# CW32L010 register map
Vendor: Wuhan Xinyuan Semiconductor Co.Ltd; Series: ARMCM0P; File version: 1.2
CPU: CM0+ r0p1, little endian, no MPU, no FPU, 3 interrupt priority bits
Registers are 32-bit, read-write, no defined reset value unless marked. A register's access mark holds for its fields unless they carry their own. Offsets are from the block's base; [hi:lo] are bit positions; {n}, {i} and the like mark numbered series; 'fields as' and 'values as' point back to an identical list.

## BTIM1 — Base Timer 1
Base 0x40004800
Same registers: BTIM2 0x40004840, BTIM3 0x40004880
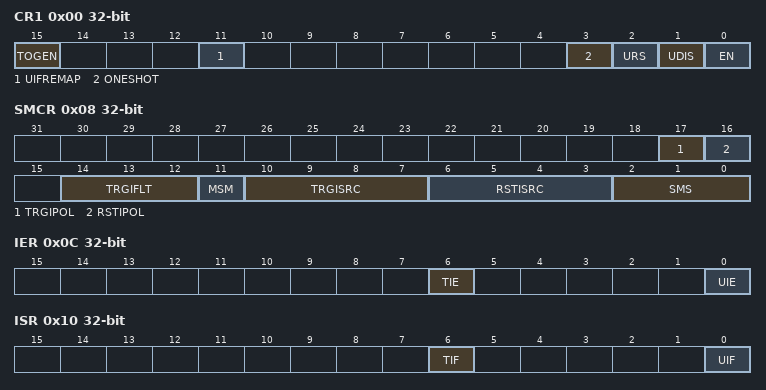
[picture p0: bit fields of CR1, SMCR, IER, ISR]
0x00 CR1 — Control register1
  [15] TOGEN
  [11] UIFREMAP — desc REMAP
  [3] ONESHOT
  [2] URS
  [1] UDIS
  [0] EN
0x04 CR2 — Control register2
  [6:4] MMS
0x08 SMCR — Slave Mode Control register
  [17] TRGIPOL, [16] RSTIPOL, [14:12] TRGIFLT, [11] MSM, [10:7] TRGISRC, [6:3] RSTISRC, [2:0] SMS
0x0C IER — Interrupt enable register
  [6] TIE, [0] UIE
0x10 ISR ro — Interrupt status register
  [6] TIF, [0] UIF
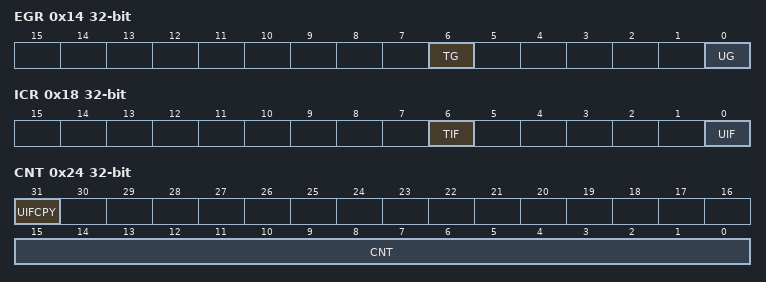
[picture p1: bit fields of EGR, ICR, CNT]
0x14 EGR wo — Event Generate register
  [6] TG, [0] UG
0x18 ICR — Interrupt flag clear register
  [6] TIF, [0] UIF
0x24 CNT — Counter Register
  [31] UIFCPY ro, [15:0] CNT
0x28 PSC — Prescaler Control Register
  [15:0] PSC
0x2C ARR — Auto Reload Register
  [15:0] ARR

## CRC
Base 0x40023000
0x00 CR — Control register
  [3:0] MODE
0x08 DR — Data register
  [7:0] DR
0x0C RESULT ro
  [15:0] RESULT

## FLASH
Base 0x40022000
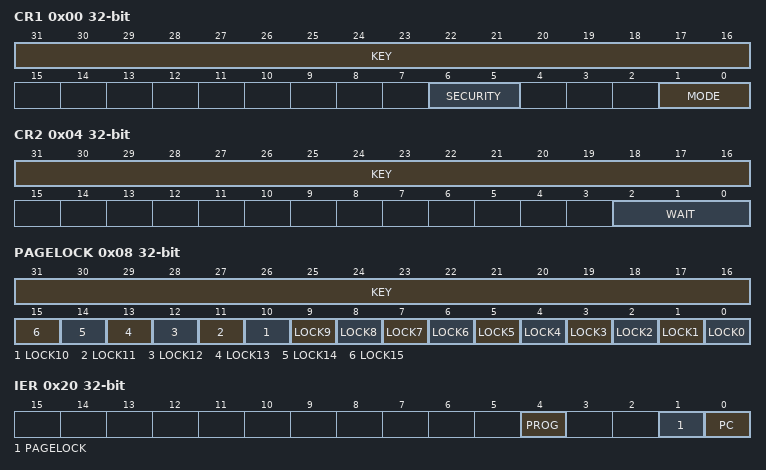
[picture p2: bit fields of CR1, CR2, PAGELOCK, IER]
0x00 CR1 — Control register1
  [31:16] KEY wo, [6:5] SECURITY ro, [1:0] MODE
0x04 CR2 — Control register2
  [31:16] KEY wo, [2:0] WAIT
0x08 PAGELOCK — Page Write Erase Lock
  [31:16] KEY wo
  [n] LOCK{n} (n=0..15) — Page{8n} - {8n+7}
0x20 IER — Interrupt enable register
  [4] PROG, [1] PAGELOCK, [0] PC
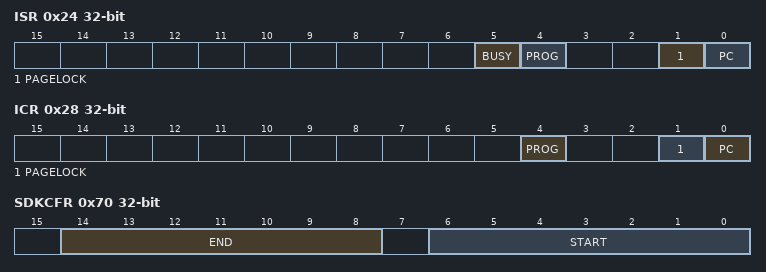
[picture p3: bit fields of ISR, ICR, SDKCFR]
0x24 ISR ro — Interrupt status register
  [5] BUSY, [4] PROG, [1] PAGELOCK, [0] PC
0x28 ICR — Interrupt flag clear register
  [4] PROG, [1] PAGELOCK, [0] PC
0x70 SDKCFR ro — SDK config register
  [14:8] END, [6:0] START

## GPIOA
Base 0x48000000
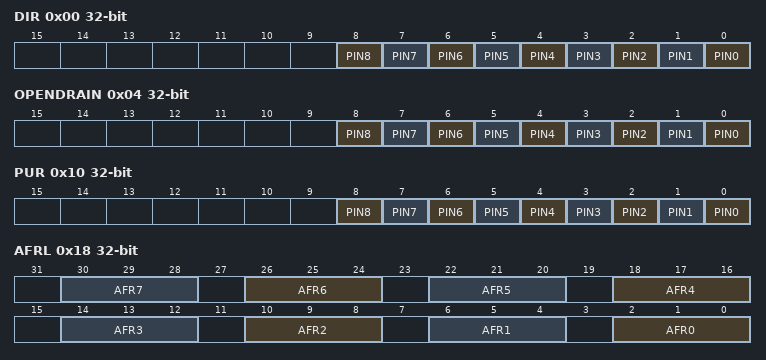
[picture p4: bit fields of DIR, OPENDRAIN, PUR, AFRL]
0x00 DIR
  [n] PIN{n} (n=0..8)
0x04 OPENDRAIN
  [n] PIN{n} (n=0..8)
0x10 PUR
  [n] PIN{n} (n=0..8)
0x14 AFRH
  [2:0] AFR8
0x18 AFRL
  [4n+2:4n] AFR{n} (n=0..7)
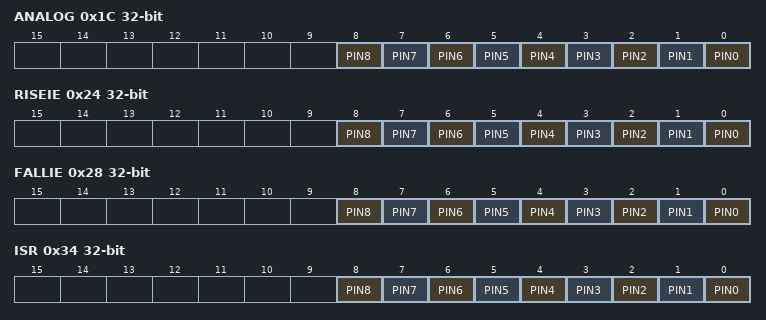
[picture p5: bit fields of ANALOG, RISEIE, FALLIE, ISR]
0x1C ANALOG
  [n] PIN{n} (n=0..8)
0x24 RISEIE — Interrupt enable register
  [n] PIN{n} (n=0..8)
0x28 FALLIE — Interrupt enable register
  [n] PIN{n} (n=0..8)
0x34 ISR — Interrupt status register
  [n] PIN{n} (n=0..8)
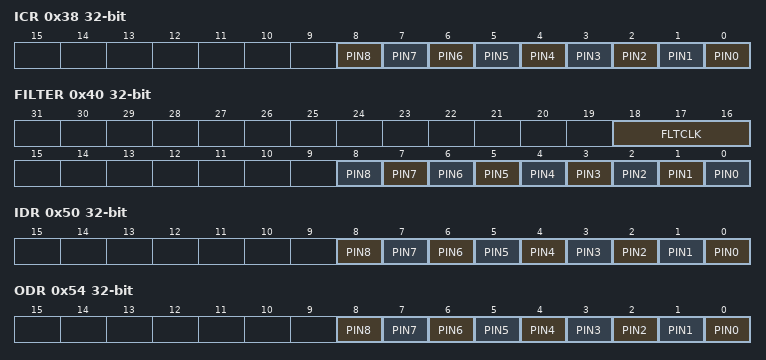
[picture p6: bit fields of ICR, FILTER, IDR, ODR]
0x38 ICR — Interrupt flag clear register
  [n] PIN{n} (n=0..8)
0x40 FILTER
  [18:16] FLTCLK, [n] PIN{n} (n=0..8)
0x50 IDR
  [n] PIN{n} (n=0..8)
0x54 ODR
  [n] PIN{n} (n=0..8)
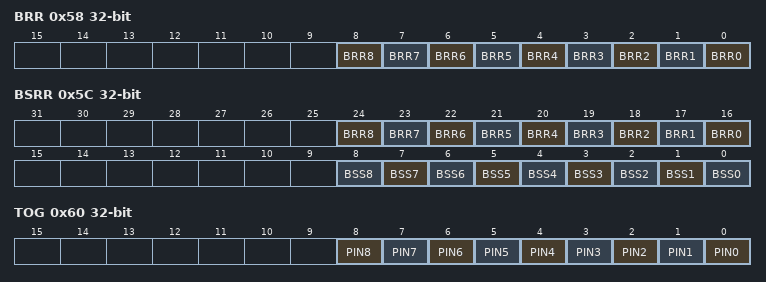
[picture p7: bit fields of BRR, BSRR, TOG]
0x58 BRR
  [n] BRR{n} (n=0..8)
0x5C BSRR
  [n+16] BRR{n} (n=0..8), [n] BSS{n} (n=0..8)
0x60 TOG
  [n] PIN{n} (n=0..8)

## GPIOB
Base 0x48000100
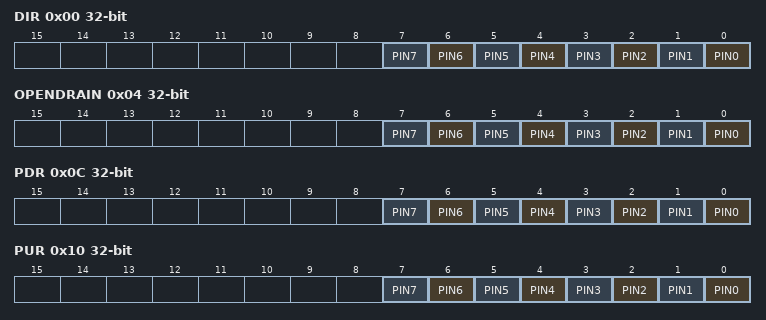
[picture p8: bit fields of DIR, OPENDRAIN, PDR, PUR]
0x00 DIR
  [n] PIN{n} (n=0..7)
0x04 OPENDRAIN
  [n] PIN{n} (n=0..7)
0x0C PDR
  [n] PIN{n} (n=0..7)
0x10 PUR
  [n] PIN{n} (n=0..7)
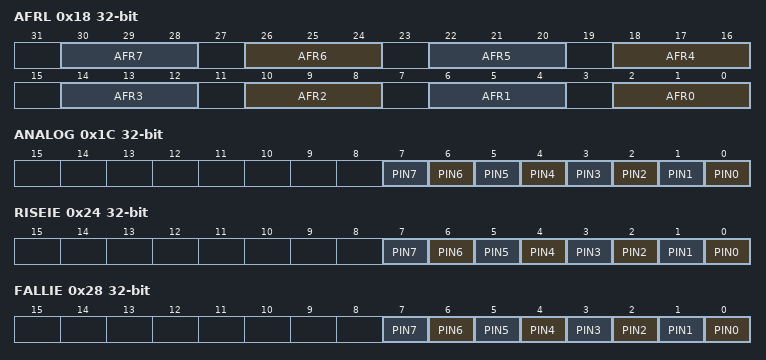
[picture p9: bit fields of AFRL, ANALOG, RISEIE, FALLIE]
0x18 AFRL
  [4n+2:4n] AFR{n} (n=0..7)
0x1C ANALOG
  [n] PIN{n} (n=0..7)
0x24 RISEIE — Interrupt enable register
  [n] PIN{n} (n=0..7)
0x28 FALLIE — Interrupt enable register
  [n] PIN{n} (n=0..7)
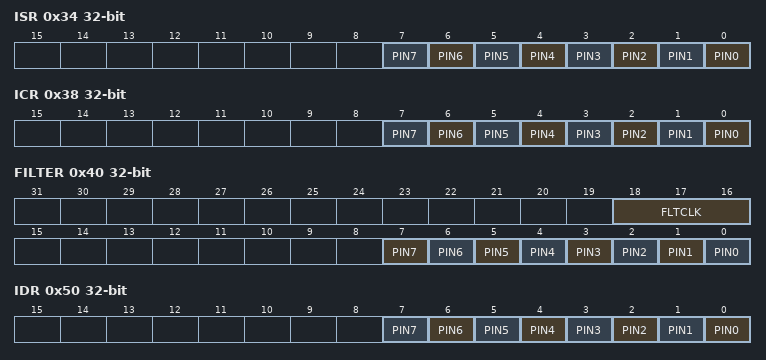
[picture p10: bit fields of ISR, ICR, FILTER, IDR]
0x34 ISR — Interrupt status register
  [n] PIN{n} (n=0..7)
0x38 ICR — Interrupt flag clear register
  [n] PIN{n} (n=0..7)
0x40 FILTER
  [18:16] FLTCLK, [n] PIN{n} (n=0..7)
0x50 IDR
  [n] PIN{n} (n=0..7)
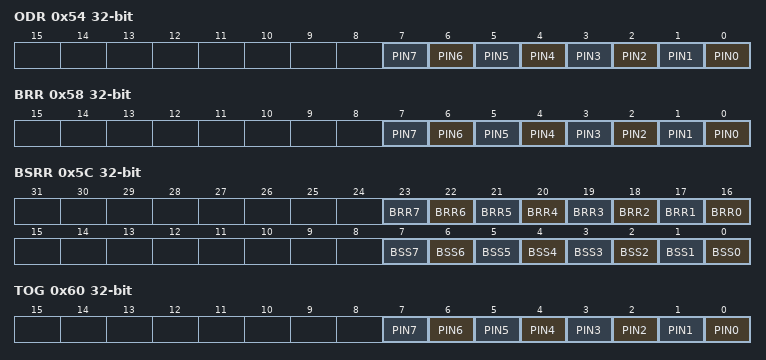
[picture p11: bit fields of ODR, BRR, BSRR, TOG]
0x54 ODR
  [n] PIN{n} (n=0..7)
0x58 BRR
  [n] PIN{n} (n=0..7)
0x5C BSRR
  [n+16] BRR{n} (n=0..7), [n] BSS{n} (n=0..7)
0x60 TOG
  [n] PIN{n} (n=0..7)

## GTIM1 — General Timer 1
Base 0x40001800
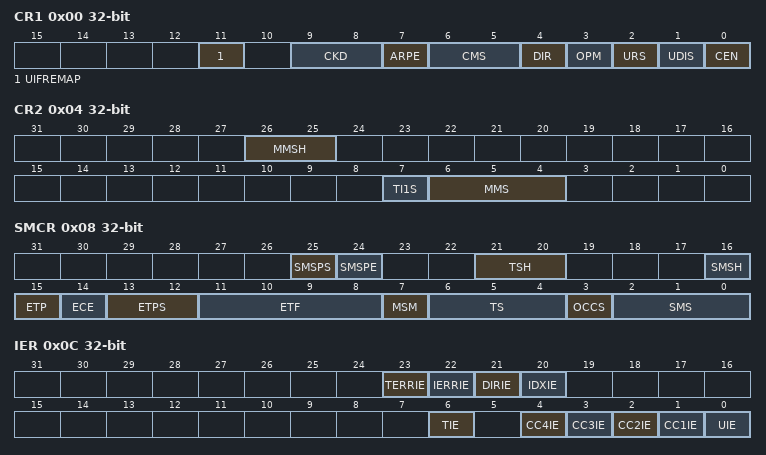
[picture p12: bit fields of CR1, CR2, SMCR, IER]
0x00 CR1 — Control register1
  [11] UIFREMAP, [9:8] CKD, [7] ARPE, [6:5] CMS, [4] DIR, [3] OPM, [2] URS, [1] UDIS, [0] CEN
0x04 CR2 — Control register2
  [26:25] MMSH, [7] TI1S, [6:4] MMS
0x08 SMCR — Slave Mode control register
  [25] SMSPS, [24] SMSPE, [21:20] TSH, [16] SMSH, [15] ETP, [14] ECE, [13:12] ETPS, [11:8] ETF, [7] MSM, [6:4] TS, [3] OCCS, [2:0] SMS
0x0C IER — Interrupt control register
  [23] TERRIE, [22] IERRIE, [21] DIRIE, [20] IDXIE, [6] TIE, [n] CC{n}IE (n=1..4), [0] UIE
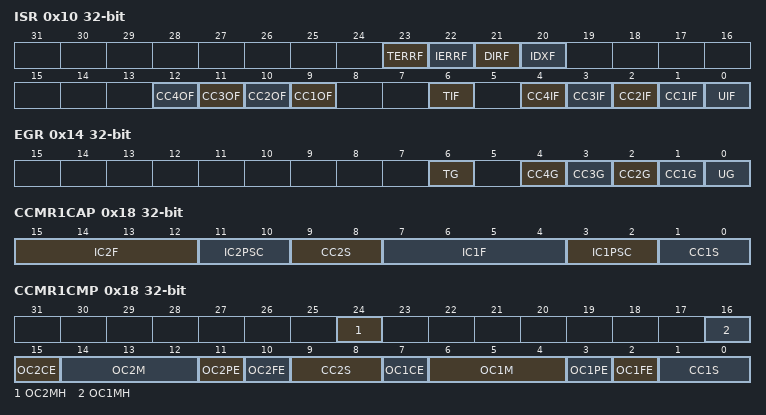
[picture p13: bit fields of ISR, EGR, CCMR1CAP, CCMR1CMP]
0x10 ISR — Interrupt status register
  [23] TERRF, [22] IERRF, [21] DIRF, [20] IDXF, [n+8] CC{n}OF (n=1..4), [6] TIF, [n] CC{n}IF (n=1..4), [0] UIF
0x14 EGR — Event Generate register
  [6] TG, [n] CC{n}G (n=1..4), [0] UG
0x18 CCMR1CAP — Capture control Register1
  [15:12] IC2F, [11:10] IC2PSC, [9:8] CC2S, [7:4] IC1F, [3:2] IC1PSC, [1:0] CC1S
0x18 CCMR1CMP (alternate view of CCMR1CAP) — Compare control Register1
  [24] OC2MH, [16] OC1MH, [15] OC2CE, [14:12] OC2M, [11] OC2PE, [10] OC2FE, [9:8] CC2S, [7] OC1CE, [6:4] OC1M, [3] OC1PE, [2] OC1FE, [1:0] CC1S
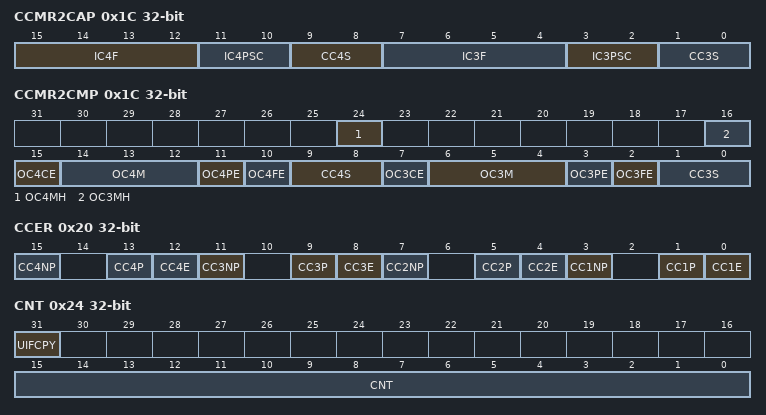
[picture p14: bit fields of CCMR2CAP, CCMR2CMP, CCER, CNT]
0x1C CCMR2CAP — Capture control Register2
  [15:12] IC4F, [11:10] IC4PSC, [9:8] CC4S, [7:4] IC3F, [3:2] IC3PSC, [1:0] CC3S
0x1C CCMR2CMP (alternate view of CCMR2CAP) — Compare control Register2
  [24] OC4MH, [16] OC3MH, [15] OC4CE, [14:12] OC4M, [11] OC4PE, [10] OC4FE, [9:8] CC4S, [7] OC3CE, [6:4] OC3M, [3] OC3PE, [2] OC3FE, [1:0] CC3S
0x20 CCER — Capture compare Enable Register
  [4n-1] CC{n}NP (n=1..4), [4n-3] CC{n}P (n=1..4), [4n-4] CC{n}E (n=1..4)
0x24 CNT — Counter Register
  [31] UIFCPY ro, [15:0] CNT
0x28 PSC — Prescaler Control Register
  [15:0] PSC
0x2C ARR — Auto Reload Register
  [15:0] ARR
{0x30+4i} CCR{i} (i=1..4) — Capture control Register{i}
  [15:0] CCR{i}
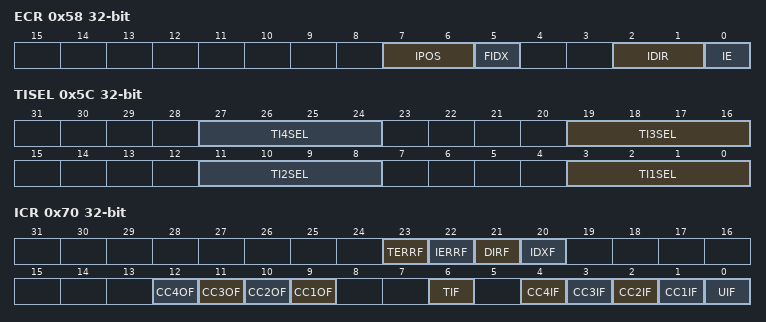
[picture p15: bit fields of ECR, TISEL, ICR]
0x58 ECR — Encoder control Register
  [7:6] IPOS, [5] FIDX, [2:1] IDIR, [0] IE
0x5C TISEL — Timer Input Select Register
  [8n-5:8n-8] TI{n}SEL (n=1..4)
0x60 AF1 — Alternate function Register1
  [17:14] ETRSEL
0x64 AF2 — Alternate function Register2
  [18:16] OCRSEL
0x70 ICR — Interrupt flag clear register
  fields as ISR
